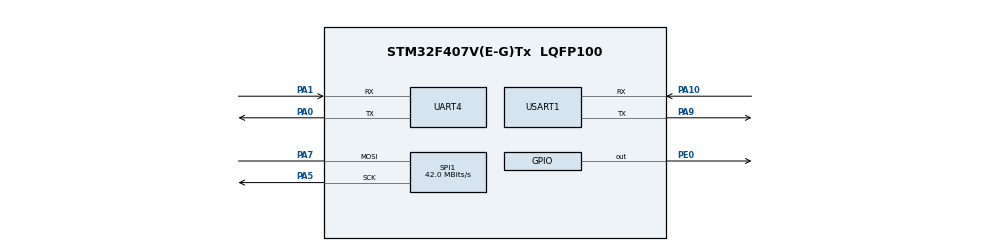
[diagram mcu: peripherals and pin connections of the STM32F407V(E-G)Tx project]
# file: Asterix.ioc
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FREERTOS.Tasks01=defaultTask,24,128,StartDefaultTask,Default,NULL
Mcu.Family=STM32F4
Mcu.Name=STM32F407V(E-G)Tx
Mcu.Package=LQFP100
NVIC.PriorityGroup=NVIC_PRIORITYGROUP_4
PA0-WKUP.Mode=Asynchronous
PA0-WKUP.Signal=UART4_TX
PA1.Mode=Asynchronous
PA1.Signal=UART4_RX
PA10.Mode=Asynchronous
PA10.Signal=USART1_RX
PA5.Mode=Simplex_Bidirectional_Master
PA5.Signal=SPI1_SCK
PA7.Mode=Simplex_Bidirectional_Master
PA7.Signal=SPI1_MOSI
PA9.Mode=Asynchronous
PA9.Signal=USART1_TX
PE0.Signal=GPIO_Output
ProjectManager.HeapSize=0x200
ProjectManager.StackSize=0x400
ProjectManager.TargetToolchain=STM32CubeIDE
RCC.48MHZClocksFreq_Value=84000000
RCC.AHBFreq_Value=168000000
RCC.APB1CLKDivider=RCC_HCLK_DIV4
RCC.APB1Freq_Value=42000000
RCC.APB1TimFreq_Value=84000000
RCC.APB2CLKDivider=RCC_HCLK_DIV2
RCC.APB2Freq_Value=84000000
RCC.APB2TimFreq_Value=168000000
RCC.CortexFreq_Value=168000000
RCC.HCLKFreq_Value=168000000
RCC.HSE_VALUE=25000000
RCC.HSI_VALUE=16000000
RCC.LSE_VALUE=32768
RCC.PLLM=8
RCC.PLLN=168
RCC.SYSCLKFreq_VALUE=168000000
RCC.SYSCLKSource=RCC_SYSCLKSOURCE_PLLCLK
RCC.VCOOutputFreq_Value=336000000
SPI1.CalculateBaudRate=42.0 MBits/s
SPI1.Direction=SPI_DIRECTION_1LINE
SPI1.Mode=SPI_MODE_MASTER
SPI1.VirtualType=VM_MASTER
UART4.VirtualMode=Asynchronous
USART1.VirtualMode=VM_ASYNC
VP_FREERTOS_VS_CMSIS_V2.Mode=CMSIS_V2
board=custom

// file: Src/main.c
/* USER CODE BEGIN Header */
/**
  ******************************************************************************
  * @file           : main.c
  * @brief          : Main program body
  ******************************************************************************
  * @attention
  *
  * <h2><center>&copy; Copyright (c) 2019 STMicroelectronics.
  * All rights reserved.</center></h2>
  *
  * This software component is licensed by ST under BSD 3-Clause license,
  * the "License"; You may not use this file except in compliance with the
  * License. You may obtain a copy of the License at:
  *                        opensource.org/licenses/BSD-3-Clause
  *
  ******************************************************************************
  */
/* USER CODE END Header */

#include "global.h"

SPI_HandleTypeDef hspi1;
UART_HandleTypeDef huart4;
UART_HandleTypeDef huart1;

osThreadId_t defaultTaskHandle;

static void MX_GPIO_Init(void);
static void MX_SPI1_Init(void);
static void MX_UART4_Init(void);
static void MX_USART1_UART_Init(void);
void StartDefaultTask(void *argument);

extern void initialise_monitor_handles(void);

int main(void)
{
  /* USER CODE BEGIN 1 */
	initialise_monitor_handles();
	printf("Asterix for Testing \n");
	tester();
	cekfungsi();

  /* USER CODE END 1 */

  /* MCU Configuration--------------------------------------------------------*/

  /* Reset of all peri
   * pherals, Initializes the Flash interface and the Systick. */
  HAL_Init();

  /* Configure the system clock */
  SystemClock_Config();

  /* Initialize all configured peripherals */
  MX_GPIO_Init();
  MX_SPI1_Init();
  MX_UART4_Init();
  MX_USART1_UART_Init();

  osKernelInitialize();

  /* Create the thread(s) */
  /* definition and creation of defaultTask */
  const osThreadAttr_t defaultTask_attributes = {
    .name = "defaultTask",
    .priority = (osPriority_t) osPriorityNormal,
    .stack_size = 128
  };
  defaultTaskHandle = osThreadNew(StartDefaultTask, NULL, &defaultTask_attributes);

  /* Start scheduler */
  osKernelStart();

  /* We should never get here as control is now taken by the scheduler */

  /* Infinite loop */
  while (1)
  {

  }
}

static void MX_SPI1_Init(void)
{

  /* SPI1 parameter configuration*/
  hspi1.Instance = SPI1;
  hspi1.Init.Mode = SPI_MODE_MASTER;
  hspi1.Init.Direction = SPI_DIRECTION_1LINE;
  hspi1.Init.DataSize = SPI_DATASIZE_8BIT;
  hspi1.Init.CLKPolarity = SPI_POLARITY_LOW;
  hspi1.Init.CLKPhase = SPI_PHASE_1EDGE;
  hspi1.Init.NSS = SPI_NSS_SOFT;
  hspi1.Init.BaudRatePrescaler = SPI_BAUDRATEPRESCALER_2;
  hspi1.Init.FirstBit = SPI_FIRSTBIT_MSB;
  hspi1.Init.TIMode = SPI_TIMODE_DISABLE;
  hspi1.Init.CRCCalculation = SPI_CRCCALCULATION_DISABLE;
  hspi1.Init.CRCPolynomial = 10;
  if (HAL_SPI_Init(&hspi1) != HAL_OK)
  {
    Error_Handler();
  }

}

static void MX_UART4_Init(void)
{

  huart4.Instance = UART4;
  huart4.Init.BaudRate = 115200;
  huart4.Init.WordLength = UART_WORDLENGTH_8B;
  huart4.Init.StopBits = UART_STOPBITS_1;
  huart4.Init.Parity = UART_PARITY_NONE;
  huart4.Init.Mode = UART_MODE_TX_RX;
  huart4.Init.HwFlowCtl = UART_HWCONTROL_NONE;
  huart4.Init.OverSampling = UART_OVERSAMPLING_16;
  if (HAL_UART_Init(&huart4) != HAL_OK)
  {
    Error_Handler();
  }

}

static void MX_USART1_UART_Init(void)
{

  huart1.Instance = USART1;
  huart1.Init.BaudRate = 115200;
  huart1.Init.WordLength = UART_WORDLENGTH_8B;
  huart1.Init.StopBits = UART_STOPBITS_1;
  huart1.Init.Parity = UART_PARITY_NONE;
  huart1.Init.Mode = UART_MODE_TX_RX;
  huart1.Init.HwFlowCtl = UART_HWCONTROL_NONE;
  huart1.Init.OverSampling = UART_OVERSAMPLING_16;
  if (HAL_UART_Init(&huart1) != HAL_OK)
  {
    Error_Handler();
  }

}

static void MX_GPIO_Init(void)
{
  GPIO_InitTypeDef GPIO_InitStruct = {0};

  /* GPIO Ports Clock Enable */
  __HAL_RCC_GPIOA_CLK_ENABLE();
  __HAL_RCC_GPIOE_CLK_ENABLE();

  /*Configure GPIO pin Output Level */
  HAL_GPIO_WritePin(GPIOE, GPIO_PIN_0, GPIO_PIN_RESET);

  /*Configure GPIO pin : PE0 */
  GPIO_InitStruct.Pin = GPIO_PIN_0;
  GPIO_InitStruct.Mode = GPIO_MODE_OUTPUT_PP;
  GPIO_InitStruct.Pull = GPIO_NOPULL;
  GPIO_InitStruct.Speed = GPIO_SPEED_FREQ_LOW;
  HAL_GPIO_Init(GPIOE, &GPIO_InitStruct);

}

void StartDefaultTask(void *argument)
{

  /* USER CODE BEGIN 5 */
  /* Infinite loop */
  for(;;)
  {
	HAL_GPIO_WritePin(GPIOE, GPIO_PIN_0, GPIO_PIN_RESET);
    osDelay(1000);
	HAL_GPIO_WritePin(GPIOE, GPIO_PIN_0, GPIO_PIN_SET);
    osDelay(1000);

    printf("hello world from task1\n");
  }
  /* USER CODE END 5 */
}

void Error_Handler(void)
{
}

/************************ (C) COPYRIGHT STMicroelectronics *****END OF FILE****/
